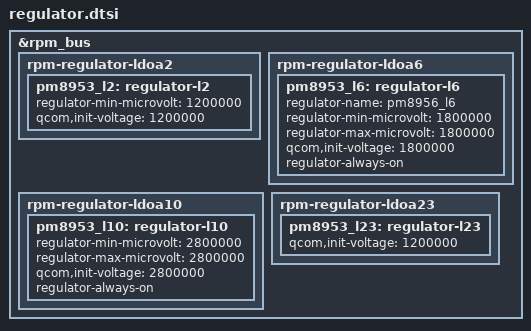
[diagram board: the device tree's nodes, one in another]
/* msm8917-regulator */

&rpm_bus {
	rpm-regulator-ldoa2 {
		pm8953_l2: regulator-l2 {
			regulator-min-microvolt = <1200000>;
			qcom,init-voltage = <1200000>;
		};
	};
};

&rpm_bus {
       rpm-regulator-ldoa6 {
		status = "okay";
		pm8953_l6: regulator-l6 {
			regulator-name = "pm8956_l6";
			regulator-min-microvolt = <1800000>;
			regulator-max-microvolt = <1800000>;
			qcom,init-voltage = <1800000>;
			status = "okay";
			regulator-always-on;
		};
	}; 
};

/* msm8953-regulator */

&rpm_bus {
	rpm-regulator-ldoa10 {
		pm8953_l10: regulator-l10 {
			regulator-min-microvolt = <2800000>;
			regulator-max-microvolt = <2800000>;
			qcom,init-voltage = <2800000>;
			regulator-always-on;
		};
	};
};

&rpm_bus {
	rpm-regulator-ldoa23 {
		pm8953_l23: regulator-l23 {
			qcom,init-voltage = <1200000>;
		};
	};
};
